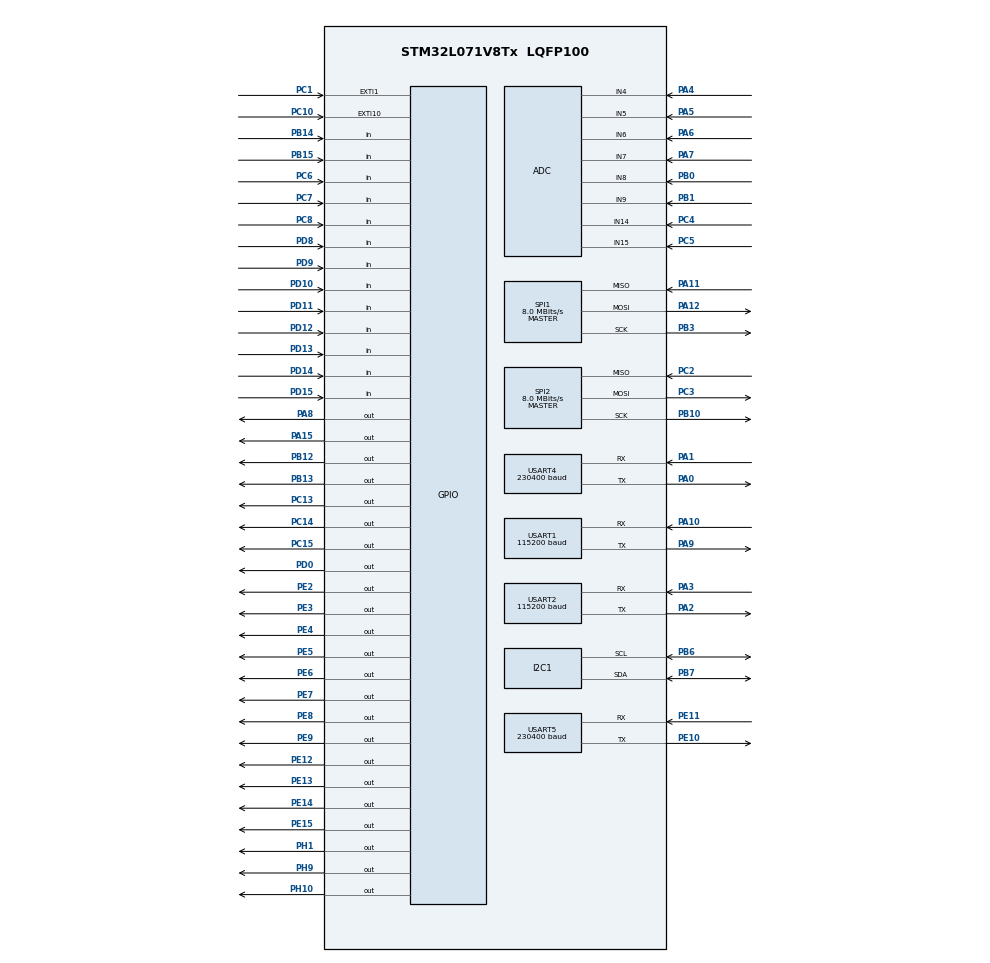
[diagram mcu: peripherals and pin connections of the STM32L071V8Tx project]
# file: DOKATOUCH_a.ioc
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CRC.InputDataFormat=CRC_INPUTDATA_FORMAT_HALFWORDS
I2C1.Timing=0x00303D5B
Mcu.Family=STM32L0
Mcu.Name=STM32L071V8Tx
Mcu.Package=LQFP100
NVIC.TIM2_IRQn=true\:0\:0\:false\:false\:true\:true\:true\:true
NVIC.USART1_IRQn=true\:0\:0\:false\:false\:true\:true\:true\:true
NVIC.USART2_IRQn=true\:0\:0\:false\:false\:true\:true\:true\:true
NVIC.USART4_5_IRQn=true\:0\:0\:false\:false\:true\:true\:true\:true
PA0.Mode=Asynchronous
PA0.Signal=USART4_TX
PA1.Mode=Asynchronous
PA1.Signal=USART4_RX
PA10.Mode=Asynchronous
PA10.Signal=USART1_RX
PA11.Mode=Full_Duplex_Master
PA11.Signal=SPI1_MISO
PA12.Mode=Full_Duplex_Master
PA12.Signal=SPI1_MOSI
PA13.Mode=Serial_Wire
PA13.Signal=SYS_SWDIO
PA14.Mode=Serial_Wire
PA14.Signal=SYS_SWCLK
PA15.Signal=GPIO_Output
PA2.Mode=Asynchronous
PA2.Signal=USART2_TX
PA3.Mode=Asynchronous
PA3.Signal=USART2_RX
PA4.Mode=IN4
PA4.Signal=ADC_IN4
PA5.Mode=IN5
PA5.Signal=ADC_IN5
PA6.Mode=IN6
PA6.Signal=ADC_IN6
PA7.Mode=IN7
PA7.Signal=ADC_IN7
PA8.Signal=GPIO_Output
PA9.Mode=Asynchronous
PA9.Signal=USART1_TX
PB0.Mode=IN8
PB0.Signal=ADC_IN8
PB1.Mode=IN9
PB1.Signal=ADC_IN9
PB10.Mode=Full_Duplex_Master
PB10.Signal=SPI2_SCK
PB12.Signal=GPIO_Output
PB13.Signal=GPIO_Output
PB14.Signal=GPIO_Input
PB15.Signal=GPIO_Input
PB3.Mode=Full_Duplex_Master
PB3.Signal=SPI1_SCK
PB6.Mode=I2C
PB6.Signal=I2C1_SCL
PB7.Mode=I2C
PB7.Signal=I2C1_SDA
PC1.Signal=GPXTI1
PC10.Signal=GPXTI10
PC13.Signal=GPIO_Output
PC14-OSC32_IN.Signal=GPIO_Output
PC15-OSC32_OUT.Signal=GPIO_Output
PC2.Mode=Full_Duplex_Master
PC2.Signal=SPI2_MISO
PC3.Mode=Full_Duplex_Master
PC3.Signal=SPI2_MOSI
PC4.Mode=IN14
PC4.Signal=ADC_IN14
PC5.Mode=IN15
PC5.Signal=ADC_IN15
PC6.Signal=GPIO_Input
PC7.Signal=GPIO_Input
PC8.Signal=GPIO_Input
PD0.Signal=GPIO_Output
PD10.Signal=GPIO_Input
PD11.Signal=GPIO_Input
PD12.Signal=GPIO_Input
PD13.Signal=GPIO_Input
PD14.Signal=GPIO_Input
PD15.Signal=GPIO_Input
PD8.Signal=GPIO_Input
PD9.Signal=GPIO_Input
PE10.Mode=Asynchronous
PE10.Signal=USART5_TX
PE11.Mode=Asynchronous
PE11.Signal=USART5_RX
PE12.Signal=GPIO_Output
PE13.Signal=GPIO_Output
PE14.Signal=GPIO_Output
PE15.Signal=GPIO_Output
PE2.Signal=GPIO_Output
PE3.Signal=GPIO_Output
PE4.Signal=GPIO_Output
PE5.Signal=GPIO_Output
PE6.Signal=GPIO_Output
PE7.Signal=GPIO_Output
PE8.Signal=GPIO_Output
PE9.Signal=GPIO_Output
PH1-OSC_OUT.Signal=GPIO_Output
PH10.Signal=GPIO_Output
PH9.Signal=GPIO_Output
ProjectManager.HeapSize=0x200
ProjectManager.StackSize=0x400
ProjectManager.TargetToolchain=MDK-ARM V5
RCC.AHBFreq_Value=16000000
RCC.APB1Freq_Value=16000000
RCC.APB1TimFreq_Value=16000000
RCC.APB2Freq_Value=16000000
RCC.APB2TimFreq_Value=16000000
RCC.HCLKFreq_Value=16000000
RCC.HSE_VALUE=8000000
RCC.HSI16_VALUE=16000000
RCC.HSI_VALUE=16000000
RCC.LSE_VALUE=32768
RCC.MSI_VALUE=2097000
RCC.PLLMUL=RCC_PLLMUL_4
RCC.SYSCLKFreq_VALUE=16000000
RCC.SYSCLKSource=RCC_SYSCLKSOURCE_HSI
RCC.VCOOutputFreq_Value=64000000
SPI1.CalculateBaudRate=8.0 MBits/s
SPI1.Direction=SPI_DIRECTION_2LINES
SPI1.Mode=SPI_MODE_MASTER
SPI1.VirtualType=VM_MASTER
SPI2.CalculateBaudRate=8.0 MBits/s
SPI2.Direction=SPI_DIRECTION_2LINES
SPI2.Mode=SPI_MODE_MASTER
SPI2.VirtualType=VM_MASTER
USART1.BaudRate=115200
USART1.Parity=PARITY_NONE
USART1.VirtualMode-Asynchronous=VM_ASYNC
USART1.WordLength=WORDLENGTH_8B
USART2.BaudRate=115200
USART2.VirtualMode-Asynchronous=VM_ASYNC
USART2.WordLength=WORDLENGTH_8B
USART4.BaudRate=230400
USART4.Parity=PARITY_NONE
USART4.VirtualMode-Asynchronous=VM_ASYNC
USART4.WordLength=WORDLENGTH_8B
USART5.BaudRate=230400
USART5.Parity=PARITY_NONE
USART5.VirtualMode-Asynchronous=VM_ASYNC
USART5.WordLength=WORDLENGTH_8B
VP_CRC_VS_CRC.Mode=CRC_Activate
VP_TIM2_VS_ClockSourceINT.Mode=Internal
board=DOKATOUCH_a

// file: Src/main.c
/**
  ******************************************************************************
  * File Name          : main.c
  * Description        : Main program body
  ******************************************************************************
  ** This notice applies to any and all portions of this file
  * that are not between comment pairs USER CODE BEGIN and
  * USER CODE END. Other portions of this file, whether
  * inserted by the user or by software development tools
  * are owned by their respective copyright owners.
  *
  * COPYRIGHT(c) 2024 STMicroelectronics
  *
  * Redistribution and use in source and binary forms, with or without modification,
  * are permitted provided that the following conditions are met:
  *   1. Redistributions of source code must retain the above copyright notice,
  *      this list of conditions and the following disclaimer.
  *   2. Redistributions in binary form must reproduce the above copyright notice,
  *      this list of conditions and the following disclaimer in the documentation
  *      and/or other materials provided with the distribution.
  *   3. Neither the name of STMicroelectronics nor the names of its contributors
  *      may be used to endorse or promote products derived from this software
  *      without specific prior written permission.
  *
  * THIS SOFTWARE IS PROVIDED BY THE COPYRIGHT HOLDERS AND CONTRIBUTORS "AS IS"
  * AND ANY EXPRESS OR IMPLIED WARRANTIES, INCLUDING, BUT NOT LIMITED TO, THE
  * IMPLIED WARRANTIES OF MERCHANTABILITY AND FITNESS FOR A PARTICULAR PURPOSE ARE
  * DISCLAIMED. IN NO EVENT SHALL THE COPYRIGHT HOLDER OR CONTRIBUTORS BE LIABLE
  * FOR ANY DIRECT, INDIRECT, INCIDENTAL, SPECIAL, EXEMPLARY, OR CONSEQUENTIAL
  * DAMAGES (INCLUDING, BUT NOT LIMITED TO, PROCUREMENT OF SUBSTITUTE GOODS OR
  * SERVICES; LOSS OF USE, DATA, OR PROFITS; OR BUSINESS INTERRUPTION) HOWEVER
  * CAUSED AND ON ANY THEORY OF LIABILITY, WHETHER IN CONTRACT, STRICT LIABILITY,
  * OR TORT (INCLUDING NEGLIGENCE OR OTHERWISE) ARISING IN ANY WAY OUT OF THE USE
  * OF THIS SOFTWARE, EVEN IF ADVISED OF THE POSSIBILITY OF SUCH DAMAGE.
  *
  ******************************************************************************
  */
#include "main.h"

/* USER CODE BEGIN Includes */

/*
2022.11.10 add tilt stop function.

*/

/* USER CODE END Includes */

/* USER CODE BEGIN PV */
/* Private variables ---------------------------------------------------------*/

/* USER CODE END PV */

static void LL_Init(void);
void SystemClock_Config(void);
static void MX_GPIO_Init(void);
static void MX_ADC_Init(void);
static void MX_CRC_Init(void);
static void MX_I2C1_Init(void);
static void MX_SPI1_Init(void);
static void MX_SPI2_Init(void);
static void MX_USART1_UART_Init(void);
static void MX_USART2_UART_Init(void);
static void MX_USART4_UART_Init(void);
static void MX_USART5_UART_Init(void);
static void MX_TIM2_Init(void);

/* USER CODE BEGIN PFP */
/* Private function prototypes -----------------------------------------------*/

/* USER CODE END PFP */

int main(void)
{

  /* MCU Configuration----------------------------------------------------------*/

  /* Reset of all peripherals, Initializes the Flash interface and the Systick. */
  LL_Init();

  /* Configure the system clock */
  SystemClock_Config();

  /* Initialize all configured peripherals */
  MX_GPIO_Init();
  MX_ADC_Init();
  MX_CRC_Init();
  MX_I2C1_Init();
  MX_SPI1_Init();
  MX_SPI2_Init();
  MX_USART1_UART_Init();
  MX_USART2_UART_Init();
  MX_USART4_UART_Init();
  MX_USART5_UART_Init();
  MX_TIM2_Init();

  /* USER CODE BEGIN 2 */
//	u5RxInterruptEnable();
	u4RxInterruptEnable();
	u2RxInterruptEnable();
	u1RxInterruptEnable();

	initTimers();
	initIwdg();

	initKanaPilotBH();

	pato1Off();
  blink(3);
	pato1On();

  /* USER CODE END 2 */

  /* Infinite loop */
  /* USER CODE BEGIN WHILE */
  while (1)
  {

		resetWDT();
		mainKanaPilotBH();

  /* USER CODE END WHILE */

  }

}

static void LL_Init(void)
{

  LL_APB2_GRP1_EnableClock(LL_APB2_GRP1_PERIPH_SYSCFG);
  LL_APB1_GRP1_EnableClock(LL_APB1_GRP1_PERIPH_PWR);

  /* System interrupt init*/
  /* SVC_IRQn interrupt configuration */
  NVIC_SetPriority(SVC_IRQn, 0);
  /* PendSV_IRQn interrupt configuration */
  NVIC_SetPriority(PendSV_IRQn, 0);
  /* SysTick_IRQn interrupt configuration */
  NVIC_SetPriority(SysTick_IRQn, 0);

}

/** System Clock Configuration
*/
void SystemClock_Config(void)
{

  LL_FLASH_SetLatency(LL_FLASH_LATENCY_0);

  if(LL_FLASH_GetLatency() != LL_FLASH_LATENCY_0)
  {
  Error_Handler();
  }
  LL_PWR_SetRegulVoltageScaling(LL_PWR_REGU_VOLTAGE_SCALE1);

  LL_RCC_HSI_Enable();

   /* Wait till HSI is ready */
  while(LL_RCC_HSI_IsReady() != 1)
  {

  }
  LL_RCC_HSI_SetCalibTrimming(16);

  LL_RCC_SetAHBPrescaler(LL_RCC_SYSCLK_DIV_1);

  LL_RCC_SetAPB1Prescaler(LL_RCC_APB1_DIV_1);

  LL_RCC_SetAPB2Prescaler(LL_RCC_APB2_DIV_1);

  LL_RCC_SetSysClkSource(LL_RCC_SYS_CLKSOURCE_HSI);

   /* Wait till System clock is ready */
  while(LL_RCC_GetSysClkSource() != LL_RCC_SYS_CLKSOURCE_STATUS_HSI)
  {

  }
  LL_Init1msTick(16000000);

  LL_SYSTICK_SetClkSource(LL_SYSTICK_CLKSOURCE_HCLK);

  LL_SetSystemCoreClock(16000000);

  LL_RCC_SetUSARTClockSource(LL_RCC_USART1_CLKSOURCE_PCLK2);

  LL_RCC_SetUSARTClockSource(LL_RCC_USART2_CLKSOURCE_PCLK1);

  LL_RCC_SetI2CClockSource(LL_RCC_I2C1_CLKSOURCE_PCLK1);

  /* SysTick_IRQn interrupt configuration */
  NVIC_SetPriority(SysTick_IRQn, 0);
}

/* ADC init function */
static void MX_ADC_Init(void)
{

  LL_ADC_InitTypeDef ADC_InitStruct;
  LL_ADC_REG_InitTypeDef ADC_REG_InitStruct;

  LL_GPIO_InitTypeDef GPIO_InitStruct;

  /* Peripheral clock enable */
  LL_APB2_GRP1_EnableClock(LL_APB2_GRP1_PERIPH_ADC1);

  /**ADC GPIO Configuration
  PA4   ------> ADC_IN4
  PA5   ------> ADC_IN5
  PA6   ------> ADC_IN6
  PA7   ------> ADC_IN7
  PC4   ------> ADC_IN14
  PC5   ------> ADC_IN15
  PB0   ------> ADC_IN8
  PB1   ------> ADC_IN9
  */
  GPIO_InitStruct.Pin = LL_GPIO_PIN_4;
  GPIO_InitStruct.Mode = LL_GPIO_MODE_ANALOG;
  GPIO_InitStruct.Pull = LL_GPIO_PULL_NO;
  LL_GPIO_Init(GPIOA, &GPIO_InitStruct);

  GPIO_InitStruct.Pin = LL_GPIO_PIN_5;
  GPIO_InitStruct.Mode = LL_GPIO_MODE_ANALOG;
  GPIO_InitStruct.Pull = LL_GPIO_PULL_NO;
  LL_GPIO_Init(GPIOA, &GPIO_InitStruct);

  GPIO_InitStruct.Pin = LL_GPIO_PIN_6;
  GPIO_InitStruct.Mode = LL_GPIO_MODE_ANALOG;
  GPIO_InitStruct.Pull = LL_GPIO_PULL_NO;
  LL_GPIO_Init(GPIOA, &GPIO_InitStruct);

  GPIO_InitStruct.Pin = LL_GPIO_PIN_7;
  GPIO_InitStruct.Mode = LL_GPIO_MODE_ANALOG;
  GPIO_InitStruct.Pull = LL_GPIO_PULL_NO;
  LL_GPIO_Init(GPIOA, &GPIO_InitStruct);

  GPIO_InitStruct.Pin = LL_GPIO_PIN_4;
  GPIO_InitStruct.Mode = LL_GPIO_MODE_ANALOG;
  GPIO_InitStruct.Pull = LL_GPIO_PULL_NO;
  LL_GPIO_Init(GPIOC, &GPIO_InitStruct);

  GPIO_InitStruct.Pin = LL_GPIO_PIN_5;
  GPIO_InitStruct.Mode = LL_GPIO_MODE_ANALOG;
  GPIO_InitStruct.Pull = LL_GPIO_PULL_NO;
  LL_GPIO_Init(GPIOC, &GPIO_InitStruct);

  GPIO_InitStruct.Pin = LL_GPIO_PIN_0;
  GPIO_InitStruct.Mode = LL_GPIO_MODE_ANALOG;
  GPIO_InitStruct.Pull = LL_GPIO_PULL_NO;
  LL_GPIO_Init(GPIOB, &GPIO_InitStruct);

  GPIO_InitStruct.Pin = LL_GPIO_PIN_1;
  GPIO_InitStruct.Mode = LL_GPIO_MODE_ANALOG;
  GPIO_InitStruct.Pull = LL_GPIO_PULL_NO;
  LL_GPIO_Init(GPIOB, &GPIO_InitStruct);

    /**Configure Regular Channel
    */
  LL_ADC_REG_SetSequencerChannels(ADC1, LL_ADC_CHANNEL_4);

    /**Configure Regular Channel
    */
  LL_ADC_REG_SetSequencerChannels(ADC1, LL_ADC_CHANNEL_5);

    /**Configure Regular Channel
    */
  LL_ADC_REG_SetSequencerChannels(ADC1, LL_ADC_CHANNEL_6);

    /**Configure Regular Channel
    */
  LL_ADC_REG_SetSequencerChannels(ADC1, LL_ADC_CHANNEL_7);

    /**Configure Regular Channel
    */
  LL_ADC_REG_SetSequencerChannels(ADC1, LL_ADC_CHANNEL_8);

    /**Configure Regular Channel
    */
  LL_ADC_REG_SetSequencerChannels(ADC1, LL_ADC_CHANNEL_9);

    /**Configure Regular Channel
    */
  LL_ADC_REG_SetSequencerChannels(ADC1, LL_ADC_CHANNEL_14);

    /**Configure Regular Channel
    */
  LL_ADC_REG_SetSequencerChannels(ADC1, LL_ADC_CHANNEL_15);

    /**Common config
    */
  ADC_InitStruct.Resolution = LL_ADC_RESOLUTION_12B;
  ADC_InitStruct.DataAlignment = LL_ADC_DATA_ALIGN_RIGHT;
  ADC_InitStruct.LowPowerMode = LL_ADC_LP_MODE_NONE;
  LL_ADC_Init(ADC1, &ADC_InitStruct);

  ADC_REG_InitStruct.TriggerSource = LL_ADC_REG_TRIG_SOFTWARE;
  ADC_REG_InitStruct.SequencerDiscont = LL_ADC_REG_SEQ_DISCONT_DISABLE;
  ADC_REG_InitStruct.ContinuousMode = LL_ADC_REG_CONV_SINGLE;
  ADC_REG_InitStruct.DMATransfer = LL_ADC_REG_DMA_TRANSFER_LIMITED;
  ADC_REG_InitStruct.Overrun = LL_ADC_REG_OVR_DATA_PRESERVED;
  LL_ADC_REG_Init(ADC1, &ADC_REG_InitStruct);

  LL_ADC_SetClock(ADC1, LL_ADC_CLOCK_SYNC_PCLK_DIV1);

  LL_ADC_SetSamplingTimeCommonChannels(ADC1, LL_ADC_SAMPLINGTIME_1CYCLE_5);

  LL_ADC_SetOverSamplingScope(ADC1, LL_ADC_OVS_DISABLE);

  LL_ADC_SetCommonFrequencyMode(__LL_ADC_COMMON_INSTANCE(ADC1), LL_ADC_CLOCK_FREQ_MODE_HIGH);

  LL_ADC_EnableIT_EOC(ADC1);

  LL_ADC_DisableIT_EOS(ADC1);

}

/* CRC init function */
static void MX_CRC_Init(void)
{

  /* Peripheral clock enable */
  LL_AHB1_GRP1_EnableClock(LL_AHB1_GRP1_PERIPH_CRC);

  LL_CRC_SetInputDataReverseMode(CRC, LL_CRC_INDATA_REVERSE_NONE);

  LL_CRC_SetOutputDataReverseMode(CRC, LL_CRC_OUTDATA_REVERSE_NONE);

  LL_CRC_SetPolynomialCoef(CRC, LL_CRC_DEFAULT_CRC32_POLY);

  LL_CRC_SetPolynomialSize(CRC, LL_CRC_POLYLENGTH_32B);

  LL_CRC_SetInitialData(CRC, LL_CRC_DEFAULT_CRC_INITVALUE);

}

/* I2C1 init function */
static void MX_I2C1_Init(void)
{

  LL_I2C_InitTypeDef I2C_InitStruct;

  LL_GPIO_InitTypeDef GPIO_InitStruct;

  /**I2C1 GPIO Configuration
  PB6   ------> I2C1_SCL
  PB7   ------> I2C1_SDA
  */
  GPIO_InitStruct.Pin = LL_GPIO_PIN_6;
  GPIO_InitStruct.Mode = LL_GPIO_MODE_ALTERNATE;
  GPIO_InitStruct.Speed = LL_GPIO_SPEED_FREQ_VERY_HIGH;
  GPIO_InitStruct.OutputType = LL_GPIO_OUTPUT_OPENDRAIN;
  GPIO_InitStruct.Pull = LL_GPIO_PULL_UP;
  GPIO_InitStruct.Alternate = LL_GPIO_AF_1;
  LL_GPIO_Init(GPIOB, &GPIO_InitStruct);

  GPIO_InitStruct.Pin = LL_GPIO_PIN_7;
  GPIO_InitStruct.Mode = LL_GPIO_MODE_ALTERNATE;
  GPIO_InitStruct.Speed = LL_GPIO_SPEED_FREQ_VERY_HIGH;
  GPIO_InitStruct.OutputType = LL_GPIO_OUTPUT_OPENDRAIN;
  GPIO_InitStruct.Pull = LL_GPIO_PULL_UP;
  GPIO_InitStruct.Alternate = LL_GPIO_AF_1;
  LL_GPIO_Init(GPIOB, &GPIO_InitStruct);

  /* Peripheral clock enable */
  LL_APB1_GRP1_EnableClock(LL_APB1_GRP1_PERIPH_I2C1);

    /**I2C Initialization
    */
  I2C_InitStruct.PeripheralMode = LL_I2C_MODE_I2C;
  I2C_InitStruct.Timing = 0x00303D5B;
  I2C_InitStruct.AnalogFilter = LL_I2C_ANALOGFILTER_ENABLE;
  I2C_InitStruct.DigitalFilter = 0;
  I2C_InitStruct.OwnAddress1 = 0;
  I2C_InitStruct.TypeAcknowledge = LL_I2C_ACK;
  I2C_InitStruct.OwnAddrSize = LL_I2C_OWNADDRESS1_7BIT;
  LL_I2C_Init(I2C1, &I2C_InitStruct);

  LL_I2C_EnableAutoEndMode(I2C1);

  LL_I2C_SetOwnAddress2(I2C1, 0, LL_I2C_OWNADDRESS2_NOMASK);

  LL_I2C_DisableOwnAddress2(I2C1);

  LL_I2C_DisableGeneralCall(I2C1);

  LL_I2C_EnableClockStretching(I2C1);

}

/* SPI1 init function */
static void MX_SPI1_Init(void)
{

  LL_SPI_InitTypeDef SPI_InitStruct;

  LL_GPIO_InitTypeDef GPIO_InitStruct;

  /* Peripheral clock enable */
  LL_APB2_GRP1_EnableClock(LL_APB2_GRP1_PERIPH_SPI1);

  /**SPI1 GPIO Configuration
  PA11   ------> SPI1_MISO
  PA12   ------> SPI1_MOSI
  PB3   ------> SPI1_SCK
  */
  GPIO_InitStruct.Pin = LL_GPIO_PIN_11;
  GPIO_InitStruct.Mode = LL_GPIO_MODE_ALTERNATE;
  GPIO_InitStruct.Speed = LL_GPIO_SPEED_FREQ_VERY_HIGH;
  GPIO_InitStruct.OutputType = LL_GPIO_OUTPUT_PUSHPULL;
  GPIO_InitStruct.Pull = LL_GPIO_PULL_NO;
  GPIO_InitStruct.Alternate = LL_GPIO_AF_0;
  LL_GPIO_Init(GPIOA, &GPIO_InitStruct);

  GPIO_InitStruct.Pin = LL_GPIO_PIN_12;
  GPIO_InitStruct.Mode = LL_GPIO_MODE_ALTERNATE;
  GPIO_InitStruct.Speed = LL_GPIO_SPEED_FREQ_VERY_HIGH;
  GPIO_InitStruct.OutputType = LL_GPIO_OUTPUT_PUSHPULL;
  GPIO_InitStruct.Pull = LL_GPIO_PULL_NO;
  GPIO_InitStruct.Alternate = LL_GPIO_AF_0;
  LL_GPIO_Init(GPIOA, &GPIO_InitStruct);

  GPIO_InitStruct.Pin = LL_GPIO_PIN_3;
  GPIO_InitStruct.Mode = LL_GPIO_MODE_ALTERNATE;
  GPIO_InitStruct.Speed = LL_GPIO_SPEED_FREQ_VERY_HIGH;
  GPIO_InitStruct.OutputType = LL_GPIO_OUTPUT_PUSHPULL;
  GPIO_InitStruct.Pull = LL_GPIO_PULL_NO;
  GPIO_InitStruct.Alternate = LL_GPIO_AF_0;
  LL_GPIO_Init(GPIOB, &GPIO_InitStruct);

  SPI_InitStruct.TransferDirection = LL_SPI_FULL_DUPLEX;
  SPI_InitStruct.Mode = LL_SPI_MODE_MASTER;
  SPI_InitStruct.DataWidth = LL_SPI_DATAWIDTH_8BIT;
  SPI_InitStruct.ClockPolarity = LL_SPI_POLARITY_LOW;
  SPI_InitStruct.ClockPhase = LL_SPI_PHASE_1EDGE;
  SPI_InitStruct.NSS = LL_SPI_NSS_SOFT;
  SPI_InitStruct.BaudRate = LL_SPI_BAUDRATEPRESCALER_DIV2;
  SPI_InitStruct.BitOrder = LL_SPI_MSB_FIRST;
  SPI_InitStruct.CRCCalculation = LL_SPI_CRCCALCULATION_DISABLE;
  SPI_InitStruct.CRCPoly = 7;
  LL_SPI_Init(SPI1, &SPI_InitStruct);

  LL_SPI_SetStandard(SPI1, LL_SPI_PROTOCOL_MOTOROLA);

}

/* SPI2 init function */
static void MX_SPI2_Init(void)
{

  LL_SPI_InitTypeDef SPI_InitStruct;

  LL_GPIO_InitTypeDef GPIO_InitStruct;

  /* Peripheral clock enable */
  LL_APB1_GRP1_EnableClock(LL_APB1_GRP1_PERIPH_SPI2);

  /**SPI2 GPIO Configuration
  PC2   ------> SPI2_MISO
  PC3   ------> SPI2_MOSI
  PB10   ------> SPI2_SCK
  */
  GPIO_InitStruct.Pin = LL_GPIO_PIN_2;
  GPIO_InitStruct.Mode = LL_GPIO_MODE_ALTERNATE;
  GPIO_InitStruct.Speed = LL_GPIO_SPEED_FREQ_VERY_HIGH;
  GPIO_InitStruct.OutputType = LL_GPIO_OUTPUT_PUSHPULL;
  GPIO_InitStruct.Pull = LL_GPIO_PULL_NO;
  GPIO_InitStruct.Alternate = LL_GPIO_AF_2;
  LL_GPIO_Init(GPIOC, &GPIO_InitStruct);

  GPIO_InitStruct.Pin = LL_GPIO_PIN_3;
  GPIO_InitStruct.Mode = LL_GPIO_MODE_ALTERNATE;
  GPIO_InitStruct.Speed = LL_GPIO_SPEED_FREQ_VERY_HIGH;
  GPIO_InitStruct.OutputType = LL_GPIO_OUTPUT_PUSHPULL;
  GPIO_InitStruct.Pull = LL_GPIO_PULL_NO;
  GPIO_InitStruct.Alternate = LL_GPIO_AF_2;
  LL_GPIO_Init(GPIOC, &GPIO_InitStruct);

  GPIO_InitStruct.Pin = LL_GPIO_PIN_10;
  GPIO_InitStruct.Mode = LL_GPIO_MODE_ALTERNATE;
  GPIO_InitStruct.Speed = LL_GPIO_SPEED_FREQ_VERY_HIGH;
  GPIO_InitStruct.OutputType = LL_GPIO_OUTPUT_PUSHPULL;
  GPIO_InitStruct.Pull = LL_GPIO_PULL_NO;
  GPIO_InitStruct.Alternate = LL_GPIO_AF_5;
  LL_GPIO_Init(GPIOB, &GPIO_InitStruct);

  SPI_InitStruct.TransferDirection = LL_SPI_FULL_DUPLEX;
  SPI_InitStruct.Mode = LL_SPI_MODE_MASTER;
  SPI_InitStruct.DataWidth = LL_SPI_DATAWIDTH_8BIT;
  SPI_InitStruct.ClockPolarity = LL_SPI_POLARITY_LOW;
  SPI_InitStruct.ClockPhase = LL_SPI_PHASE_1EDGE;
  SPI_InitStruct.NSS = LL_SPI_NSS_SOFT;
  SPI_InitStruct.BaudRate = LL_SPI_BAUDRATEPRESCALER_DIV2;
  SPI_InitStruct.BitOrder = LL_SPI_MSB_FIRST;
  SPI_InitStruct.CRCCalculation = LL_SPI_CRCCALCULATION_DISABLE;
  SPI_InitStruct.CRCPoly = 7;
  LL_SPI_Init(SPI2, &SPI_InitStruct);

  LL_SPI_SetStandard(SPI2, LL_SPI_PROTOCOL_MOTOROLA);

}

/* TIM2 init function */
static void MX_TIM2_Init(void)
{

  LL_TIM_InitTypeDef TIM_InitStruct;

  /* Peripheral clock enable */
  LL_APB1_GRP1_EnableClock(LL_APB1_GRP1_PERIPH_TIM2);

  /* TIM2 interrupt Init */
  NVIC_SetPriority(TIM2_IRQn, 0);
  NVIC_EnableIRQ(TIM2_IRQn);

  TIM_InitStruct.Prescaler = 0;
  TIM_InitStruct.CounterMode = LL_TIM_COUNTERMODE_UP;
  TIM_InitStruct.Autoreload = 0;
  TIM_InitStruct.ClockDivision = LL_TIM_CLOCKDIVISION_DIV1;
  LL_TIM_Init(TIM2, &TIM_InitStruct);

  LL_TIM_SetClockSource(TIM2, LL_TIM_CLOCKSOURCE_INTERNAL);

  LL_TIM_SetTriggerOutput(TIM2, LL_TIM_TRGO_RESET);

  LL_TIM_DisableMasterSlaveMode(TIM2);

}

/* USART1 init function */
static void MX_USART1_UART_Init(void)
{

  LL_USART_InitTypeDef USART_InitStruct;

  LL_GPIO_InitTypeDef GPIO_InitStruct;

  /* Peripheral clock enable */
  LL_APB2_GRP1_EnableClock(LL_APB2_GRP1_PERIPH_USART1);

  /**USART1 GPIO Configuration
  PA9   ------> USART1_TX
  PA10   ------> USART1_RX
  */
  GPIO_InitStruct.Pin = LL_GPIO_PIN_9;
  GPIO_InitStruct.Mode = LL_GPIO_MODE_ALTERNATE;
  GPIO_InitStruct.Speed = LL_GPIO_SPEED_FREQ_VERY_HIGH;
  GPIO_InitStruct.OutputType = LL_GPIO_OUTPUT_PUSHPULL;
  GPIO_InitStruct.Pull = LL_GPIO_PULL_UP;
  GPIO_InitStruct.Alternate = LL_GPIO_AF_4;
  LL_GPIO_Init(GPIOA, &GPIO_InitStruct);

  GPIO_InitStruct.Pin = LL_GPIO_PIN_10;
  GPIO_InitStruct.Mode = LL_GPIO_MODE_ALTERNATE;
  GPIO_InitStruct.Speed = LL_GPIO_SPEED_FREQ_VERY_HIGH;
  GPIO_InitStruct.OutputType = LL_GPIO_OUTPUT_PUSHPULL;
  GPIO_InitStruct.Pull = LL_GPIO_PULL_UP;
  GPIO_InitStruct.Alternate = LL_GPIO_AF_4;
  LL_GPIO_Init(GPIOA, &GPIO_InitStruct);

  /* USART1 interrupt Init */
  NVIC_SetPriority(USART1_IRQn, 0);
  NVIC_EnableIRQ(USART1_IRQn);

  USART_InitStruct.BaudRate = 115200;
  USART_InitStruct.DataWidth = LL_USART_DATAWIDTH_8B;
  USART_InitStruct.StopBits = LL_USART_STOPBITS_1;
  USART_InitStruct.Parity = LL_USART_PARITY_NONE;
  USART_InitStruct.TransferDirection = LL_USART_DIRECTION_TX_RX;
  USART_InitStruct.HardwareFlowControl = LL_USART_HWCONTROL_NONE;
  USART_InitStruct.OverSampling = LL_USART_OVERSAMPLING_16;
  LL_USART_Init(USART1, &USART_InitStruct);

  LL_USART_DisableOverrunDetect(USART1);

  LL_USART_ConfigAsyncMode(USART1);

  LL_USART_Enable(USART1);

}

/* USART2 init function */
static void MX_USART2_UART_Init(void)
{

  LL_USART_InitTypeDef USART_InitStruct;

  LL_GPIO_InitTypeDef GPIO_InitStruct;

  /* Peripheral clock enable */
  LL_APB1_GRP1_EnableClock(LL_APB1_GRP1_PERIPH_USART2);

  /**USART2 GPIO Configuration
  PA2   ------> USART2_TX
  PA3   ------> USART2_RX
  */
  GPIO_InitStruct.Pin = LL_GPIO_PIN_2;
  GPIO_InitStruct.Mode = LL_GPIO_MODE_ALTERNATE;
  GPIO_InitStruct.Speed = LL_GPIO_SPEED_FREQ_VERY_HIGH;
  GPIO_InitStruct.OutputType = LL_GPIO_OUTPUT_PUSHPULL;
  GPIO_InitStruct.Pull = LL_GPIO_PULL_UP;
  GPIO_InitStruct.Alternate = LL_GPIO_AF_4;
  LL_GPIO_Init(GPIOA, &GPIO_InitStruct);

  GPIO_InitStruct.Pin = LL_GPIO_PIN_3;
  GPIO_InitStruct.Mode = LL_GPIO_MODE_ALTERNATE;
  GPIO_InitStruct.Speed = LL_GPIO_SPEED_FREQ_VERY_HIGH;
  GPIO_InitStruct.OutputType = LL_GPIO_OUTPUT_PUSHPULL;
  GPIO_InitStruct.Pull = LL_GPIO_PULL_UP;
  GPIO_InitStruct.Alternate = LL_GPIO_AF_4;
  LL_GPIO_Init(GPIOA, &GPIO_InitStruct);

  /* USART2 interrupt Init */
  NVIC_SetPriority(USART2_IRQn, 0);
  NVIC_EnableIRQ(USART2_IRQn);

  USART_InitStruct.BaudRate = 115200;
  USART_InitStruct.DataWidth = LL_USART_DATAWIDTH_8B;
  USART_InitStruct.StopBits = LL_USART_STOPBITS_1;
  USART_InitStruct.Parity = LL_USART_PARITY_NONE;
  USART_InitStruct.TransferDirection = LL_USART_DIRECTION_TX_RX;
  USART_InitStruct.HardwareFlowControl = LL_USART_HWCONTROL_NONE;
  USART_InitStruct.OverSampling = LL_USART_OVERSAMPLING_16;
  LL_USART_Init(USART2, &USART_InitStruct);

  LL_USART_DisableOverrunDetect(USART2);

  LL_USART_ConfigAsyncMode(USART2);

  LL_USART_Enable(USART2);

}

/* USART4 init function */
static void MX_USART4_UART_Init(void)
{

  LL_USART_InitTypeDef USART_InitStruct;

  LL_GPIO_InitTypeDef GPIO_InitStruct;

  /* Peripheral clock enable */
  LL_APB1_GRP1_EnableClock(LL_APB1_GRP1_PERIPH_USART4);

  /**USART4 GPIO Configuration
  PA0   ------> USART4_TX
  PA1   ------> USART4_RX
  */
  GPIO_InitStruct.Pin = LL_GPIO_PIN_0;
  GPIO_InitStruct.Mode = LL_GPIO_MODE_ALTERNATE;
  GPIO_InitStruct.Speed = LL_GPIO_SPEED_FREQ_VERY_HIGH;
  GPIO_InitStruct.OutputType = LL_GPIO_OUTPUT_PUSHPULL;
  GPIO_InitStruct.Pull = LL_GPIO_PULL_UP;
  GPIO_InitStruct.Alternate = LL_GPIO_AF_6;
  LL_GPIO_Init(GPIOA, &GPIO_InitStruct);

  GPIO_InitStruct.Pin = LL_GPIO_PIN_1;
  GPIO_InitStruct.Mode = LL_GPIO_MODE_ALTERNATE;
  GPIO_InitStruct.Speed = LL_GPIO_SPEED_FREQ_VERY_HIGH;
  GPIO_InitStruct.OutputType = LL_GPIO_OUTPUT_PUSHPULL;
  GPIO_InitStruct.Pull = LL_GPIO_PULL_UP;
  GPIO_InitStruct.Alternate = LL_GPIO_AF_6;
  LL_GPIO_Init(GPIOA, &GPIO_InitStruct);

  /* USART4 interrupt Init */
  NVIC_SetPriority(USART4_5_IRQn, 0);
  NVIC_EnableIRQ(USART4_5_IRQn);

  USART_InitStruct.BaudRate = 230400;
  USART_InitStruct.DataWidth = LL_USART_DATAWIDTH_8B;
  USART_InitStruct.StopBits = LL_USART_STOPBITS_1;
  USART_InitStruct.Parity = LL_USART_PARITY_NONE;
  USART_InitStruct.TransferDirection = LL_USART_DIRECTION_TX_RX;
  USART_InitStruct.HardwareFlowControl = LL_USART_HWCONTROL_NONE;
  USART_InitStruct.OverSampling = LL_USART_OVERSAMPLING_16;
  LL_USART_Init(USART4, &USART_InitStruct);

  LL_USART_DisableOverrunDetect(USART4);

  LL_USART_ConfigAsyncMode(USART4);

  LL_USART_Enable(USART4);

}

/* USART5 init function */
static void MX_USART5_UART_Init(void)
{

  LL_USART_InitTypeDef USART_InitStruct;

  LL_GPIO_InitTypeDef GPIO_InitStruct;

  /* Peripheral clock enable */
  LL_APB1_GRP1_EnableClock(LL_APB1_GRP1_PERIPH_USART5);

  /**USART5 GPIO Configuration
  PE10   ------> USART5_TX
  PE11   ------> USART5_RX
  */
  GPIO_InitStruct.Pin = LL_GPIO_PIN_10;
  GPIO_InitStruct.Mode = LL_GPIO_MODE_ALTERNATE;
  GPIO_InitStruct.Speed = LL_GPIO_SPEED_FREQ_VERY_HIGH;
  GPIO_InitStruct.OutputType = LL_GPIO_OUTPUT_PUSHPULL;
  GPIO_InitStruct.Pull = LL_GPIO_PULL_UP;
  GPIO_InitStruct.Alternate = LL_GPIO_AF_6;
  LL_GPIO_Init(GPIOE, &GPIO_InitStruct);

  GPIO_InitStruct.Pin = LL_GPIO_PIN_11;
  GPIO_InitStruct.Mode = LL_GPIO_MODE_ALTERNATE;
  GPIO_InitStruct.Speed = LL_GPIO_SPEED_FREQ_VERY_HIGH;
  GPIO_InitStruct.OutputType = LL_GPIO_OUTPUT_PUSHPULL;
  GPIO_InitStruct.Pull = LL_GPIO_PULL_UP;
  GPIO_InitStruct.Alternate = LL_GPIO_AF_6;
  LL_GPIO_Init(GPIOE, &GPIO_InitStruct);

  /* USART5 interrupt Init */
  NVIC_SetPriority(USART4_5_IRQn, 0);
  NVIC_EnableIRQ(USART4_5_IRQn);

  USART_InitStruct.BaudRate = 230400;
  USART_InitStruct.DataWidth = LL_USART_DATAWIDTH_8B;
  USART_InitStruct.StopBits = LL_USART_STOPBITS_1;
  USART_InitStruct.Parity = LL_USART_PARITY_NONE;
  USART_InitStruct.TransferDirection = LL_USART_DIRECTION_TX_RX;
  USART_InitStruct.HardwareFlowControl = LL_USART_HWCONTROL_NONE;
  USART_InitStruct.OverSampling = LL_USART_OVERSAMPLING_16;
  LL_USART_Init(USART5, &USART_InitStruct);

  LL_USART_DisableOverrunDetect(USART5);

  LL_USART_ConfigAsyncMode(USART5);

  LL_USART_Enable(USART5);

}

/** Configure pins as
        * Analog
        * Input
        * Output
        * EVENT_OUT
        * EXTI
*/
static void MX_GPIO_Init(void)
{

  LL_EXTI_InitTypeDef EXTI_InitStruct;
  LL_GPIO_InitTypeDef GPIO_InitStruct;

  /* GPIO Ports Clock Enable */
  LL_IOP_GRP1_EnableClock(LL_IOP_GRP1_PERIPH_GPIOE);
  LL_IOP_GRP1_EnableClock(LL_IOP_GRP1_PERIPH_GPIOC);
  LL_IOP_GRP1_EnableClock(LL_IOP_GRP1_PERIPH_GPIOH);
  LL_IOP_GRP1_EnableClock(LL_IOP_GRP1_PERIPH_GPIOA);
  LL_IOP_GRP1_EnableClock(LL_IOP_GRP1_PERIPH_GPIOB);
  LL_IOP_GRP1_EnableClock(LL_IOP_GRP1_PERIPH_GPIOD);

  /**/
  LL_GPIO_ResetOutputPin(GPIOE, LL_GPIO_PIN_2);

  /**/
  LL_GPIO_ResetOutputPin(GPIOE, LL_GPIO_PIN_3);

  /**/
  LL_GPIO_ResetOutputPin(GPIOE, LL_GPIO_PIN_4);

  /**/
  LL_GPIO_ResetOutputPin(GPIOE, LL_GPIO_PIN_5);

  /**/
  LL_GPIO_ResetOutputPin(GPIOE, LL_GPIO_PIN_6);

  /**/
  LL_GPIO_ResetOutputPin(GPIOC, LL_GPIO_PIN_13);

  /**/
  LL_GPIO_ResetOutputPin(GPIOC, LL_GPIO_PIN_14);

  /**/
  LL_GPIO_ResetOutputPin(GPIOC, LL_GPIO_PIN_15);

  /**/
  LL_GPIO_ResetOutputPin(GPIOH, LL_GPIO_PIN_9);

  /**/
  LL_GPIO_ResetOutputPin(GPIOH, LL_GPIO_PIN_10);

  /**/
  LL_GPIO_ResetOutputPin(GPIOH, LL_GPIO_PIN_1);

  /**/
  LL_GPIO_ResetOutputPin(GPIOE, LL_GPIO_PIN_7);

  /**/
  LL_GPIO_ResetOutputPin(GPIOE, LL_GPIO_PIN_8);

  /**/
  LL_GPIO_ResetOutputPin(GPIOE, LL_GPIO_PIN_9);

  /**/
  LL_GPIO_ResetOutputPin(GPIOE, LL_GPIO_PIN_12);

  /**/
  LL_GPIO_ResetOutputPin(GPIOE, LL_GPIO_PIN_13);

  /**/
  LL_GPIO_ResetOutputPin(GPIOE, LL_GPIO_PIN_14);

  /**/
  LL_GPIO_ResetOutputPin(GPIOE, LL_GPIO_PIN_15);

  /**/
  LL_GPIO_ResetOutputPin(GPIOB, LL_GPIO_PIN_12);

  /**/
  LL_GPIO_ResetOutputPin(GPIOB, LL_GPIO_PIN_13);

  /**/
  LL_GPIO_ResetOutputPin(GPIOA, LL_GPIO_PIN_8);

  /**/
  LL_GPIO_ResetOutputPin(GPIOA, LL_GPIO_PIN_15);

  /**/
  LL_GPIO_ResetOutputPin(GPIOD, LL_GPIO_PIN_0);

  /**/
  GPIO_InitStruct.Pin = LL_GPIO_PIN_2;
  GPIO_InitStruct.Mode = LL_GPIO_MODE_OUTPUT;
  GPIO_InitStruct.Speed = LL_GPIO_SPEED_FREQ_LOW;
  GPIO_InitStruct.OutputType = LL_GPIO_OUTPUT_PUSHPULL;
  GPIO_InitStruct.Pull = LL_GPIO_PULL_NO;
  LL_GPIO_Init(GPIOE, &GPIO_InitStruct);

  /**/
  GPIO_InitStruct.Pin = LL_GPIO_PIN_3;
  GPIO_InitStruct.Mode = LL_GPIO_MODE_OUTPUT;
  GPIO_InitStruct.Speed = LL_GPIO_SPEED_FREQ_LOW;
  GPIO_InitStruct.OutputType = LL_GPIO_OUTPUT_PUSHPULL;
  GPIO_InitStruct.Pull = LL_GPIO_PULL_NO;
  LL_GPIO_Init(GPIOE, &GPIO_InitStruct);

  /**/
  GPIO_InitStruct.Pin = LL_GPIO_PIN_4;
  GPIO_InitStruct.Mode = LL_GPIO_MODE_OUTPUT;
  GPIO_InitStruct.Speed = LL_GPIO_SPEED_FREQ_LOW;
  GPIO_InitStruct.OutputType = LL_GPIO_OUTPUT_PUSHPULL;
  GPIO_InitStruct.Pull = LL_GPIO_PULL_NO;
  LL_GPIO_Init(GPIOE, &GPIO_InitStruct);

  /**/
  GPIO_InitStruct.Pin = LL_GPIO_PIN_5;
  GPIO_InitStruct.Mode = LL_GPIO_MODE_OUTPUT;
  GPIO_InitStruct.Speed = LL_GPIO_SPEED_FREQ_LOW;
  GPIO_InitStruct.OutputType = LL_GPIO_OUTPUT_PUSHPULL;
  GPIO_InitStruct.Pull = LL_GPIO_PULL_NO;
  LL_GPIO_Init(GPIOE, &GPIO_InitStruct);

  /**/
  GPIO_InitStruct.Pin = LL_GPIO_PIN_6;
  GPIO_InitStruct.Mode = LL_GPIO_MODE_OUTPUT;
  GPIO_InitStruct.Speed = LL_GPIO_SPEED_FREQ_LOW;
  GPIO_InitStruct.OutputType = LL_GPIO_OUTPUT_PUSHPULL;
  GPIO_InitStruct.Pull = LL_GPIO_PULL_NO;
  LL_GPIO_Init(GPIOE, &GPIO_InitStruct);

  /**/
  GPIO_InitStruct.Pin = LL_GPIO_PIN_13;
  GPIO_InitStruct.Mode = LL_GPIO_MODE_OUTPUT;
  GPIO_InitStruct.Speed = LL_GPIO_SPEED_FREQ_LOW;
  GPIO_InitStruct.OutputType = LL_GPIO_OUTPUT_PUSHPULL;
  GPIO_InitStruct.Pull = LL_GPIO_PULL_NO;
  LL_GPIO_Init(GPIOC, &GPIO_InitStruct);

  /**/
  GPIO_InitStruct.Pin = LL_GPIO_PIN_14;
  GPIO_InitStruct.Mode = LL_GPIO_MODE_OUTPUT;
  GPIO_InitStruct.Speed = LL_GPIO_SPEED_FREQ_LOW;
  GPIO_InitStruct.OutputType = LL_GPIO_OUTPUT_PUSHPULL;
  GPIO_InitStruct.Pull = LL_GPIO_PULL_NO;
  LL_GPIO_Init(GPIOC, &GPIO_InitStruct);

  /**/
  GPIO_InitStruct.Pin = LL_GPIO_PIN_15;
  GPIO_InitStruct.Mode = LL_GPIO_MODE_OUTPUT;
  GPIO_InitStruct.Speed = LL_GPIO_SPEED_FREQ_LOW;
  GPIO_InitStruct.OutputType = LL_GPIO_OUTPUT_PUSHPULL;
  GPIO_InitStruct.Pull = LL_GPIO_PULL_NO;
  LL_GPIO_Init(GPIOC, &GPIO_InitStruct);

  /**/
  GPIO_InitStruct.Pin = LL_GPIO_PIN_9;
  GPIO_InitStruct.Mode = LL_GPIO_MODE_OUTPUT;
  GPIO_InitStruct.Speed = LL_GPIO_SPEED_FREQ_LOW;
  GPIO_InitStruct.OutputType = LL_GPIO_OUTPUT_PUSHPULL;
  GPIO_InitStruct.Pull = LL_GPIO_PULL_NO;
  LL_GPIO_Init(GPIOH, &GPIO_InitStruct);

  /**/
  GPIO_InitStruct.Pin = LL_GPIO_PIN_10;
  GPIO_InitStruct.Mode = LL_GPIO_MODE_OUTPUT;
  GPIO_InitStruct.Speed = LL_GPIO_SPEED_FREQ_LOW;
  GPIO_InitStruct.OutputType = LL_GPIO_OUTPUT_PUSHPULL;
  GPIO_InitStruct.Pull = LL_GPIO_PULL_NO;
  LL_GPIO_Init(GPIOH, &GPIO_InitStruct);

  /**/
  GPIO_InitStruct.Pin = LL_GPIO_PIN_1;
  GPIO_InitStruct.Mode = LL_GPIO_MODE_OUTPUT;
  GPIO_InitStruct.Speed = LL_GPIO_SPEED_FREQ_LOW;
  GPIO_InitStruct.OutputType = LL_GPIO_OUTPUT_PUSHPULL;
  GPIO_InitStruct.Pull = LL_GPIO_PULL_NO;
  LL_GPIO_Init(GPIOH, &GPIO_InitStruct);

  /**/
  GPIO_InitStruct.Pin = LL_GPIO_PIN_7;
  GPIO_InitStruct.Mode = LL_GPIO_MODE_OUTPUT;
  GPIO_InitStruct.Speed = LL_GPIO_SPEED_FREQ_LOW;
  GPIO_InitStruct.OutputType = LL_GPIO_OUTPUT_PUSHPULL;
  GPIO_InitStruct.Pull = LL_GPIO_PULL_NO;
  LL_GPIO_Init(GPIOE, &GPIO_InitStruct);

  /**/
  GPIO_InitStruct.Pin = LL_GPIO_PIN_8;
  GPIO_InitStruct.Mode = LL_GPIO_MODE_OUTPUT;
  GPIO_InitStruct.Speed = LL_GPIO_SPEED_FREQ_LOW;
  GPIO_InitStruct.OutputType = LL_GPIO_OUTPUT_PUSHPULL;
  GPIO_InitStruct.Pull = LL_GPIO_PULL_NO;
  LL_GPIO_Init(GPIOE, &GPIO_InitStruct);

  /**/
  GPIO_InitStruct.Pin = LL_GPIO_PIN_9;
  GPIO_InitStruct.Mode = LL_GPIO_MODE_OUTPUT;
  GPIO_InitStruct.Speed = LL_GPIO_SPEED_FREQ_LOW;
  GPIO_InitStruct.OutputType = LL_GPIO_OUTPUT_PUSHPULL;
  GPIO_InitStruct.Pull = LL_GPIO_PULL_NO;
  LL_GPIO_Init(GPIOE, &GPIO_InitStruct);

  /**/
  GPIO_InitStruct.Pin = LL_GPIO_PIN_12;
  GPIO_InitStruct.Mode = LL_GPIO_MODE_OUTPUT;
  GPIO_InitStruct.Speed = LL_GPIO_SPEED_FREQ_LOW;
  GPIO_InitStruct.OutputType = LL_GPIO_OUTPUT_PUSHPULL;
  GPIO_InitStruct.Pull = LL_GPIO_PULL_NO;
  LL_GPIO_Init(GPIOE, &GPIO_InitStruct);

  /**/
  GPIO_InitStruct.Pin = LL_GPIO_PIN_13;
  GPIO_InitStruct.Mode = LL_GPIO_MODE_OUTPUT;
  GPIO_InitStruct.Speed = LL_GPIO_SPEED_FREQ_LOW;
  GPIO_InitStruct.OutputType = LL_GPIO_OUTPUT_PUSHPULL;
  GPIO_InitStruct.Pull = LL_GPIO_PULL_NO;
  LL_GPIO_Init(GPIOE, &GPIO_InitStruct);

  /**/
  GPIO_InitStruct.Pin = LL_GPIO_PIN_14;
  GPIO_InitStruct.Mode = LL_GPIO_MODE_OUTPUT;
  GPIO_InitStruct.Speed = LL_GPIO_SPEED_FREQ_LOW;
  GPIO_InitStruct.OutputType = LL_GPIO_OUTPUT_PUSHPULL;
  GPIO_InitStruct.Pull = LL_GPIO_PULL_NO;
  LL_GPIO_Init(GPIOE, &GPIO_InitStruct);

  /**/
  GPIO_InitStruct.Pin = LL_GPIO_PIN_15;
  GPIO_InitStruct.Mode = LL_GPIO_MODE_OUTPUT;
  GPIO_InitStruct.Speed = LL_GPIO_SPEED_FREQ_LOW;
  GPIO_InitStruct.OutputType = LL_GPIO_OUTPUT_PUSHPULL;
  GPIO_InitStruct.Pull = LL_GPIO_PULL_NO;
  LL_GPIO_Init(GPIOE, &GPIO_InitStruct);

  /**/
  GPIO_InitStruct.Pin = LL_GPIO_PIN_12;
  GPIO_InitStruct.Mode = LL_GPIO_MODE_OUTPUT;
  GPIO_InitStruct.Speed = LL_GPIO_SPEED_FREQ_LOW;
  GPIO_InitStruct.OutputType = LL_GPIO_OUTPUT_PUSHPULL;
  GPIO_InitStruct.Pull = LL_GPIO_PULL_NO;
  LL_GPIO_Init(GPIOB, &GPIO_InitStruct);

  /**/
  GPIO_InitStruct.Pin = LL_GPIO_PIN_13;
  GPIO_InitStruct.Mode = LL_GPIO_MODE_OUTPUT;
  GPIO_InitStruct.Speed = LL_GPIO_SPEED_FREQ_LOW;
  GPIO_InitStruct.OutputType = LL_GPIO_OUTPUT_PUSHPULL;
  GPIO_InitStruct.Pull = LL_GPIO_PULL_NO;
  LL_GPIO_Init(GPIOB, &GPIO_InitStruct);

  /**/
  GPIO_InitStruct.Pin = LL_GPIO_PIN_14;
  GPIO_InitStruct.Mode = LL_GPIO_MODE_INPUT;
  GPIO_InitStruct.Pull = LL_GPIO_PULL_NO;
  LL_GPIO_Init(GPIOB, &GPIO_InitStruct);

  /**/
  GPIO_InitStruct.Pin = LL_GPIO_PIN_15;
  GPIO_InitStruct.Mode = LL_GPIO_MODE_INPUT;
  GPIO_InitStruct.Pull = LL_GPIO_PULL_NO;
  LL_GPIO_Init(GPIOB, &GPIO_InitStruct);

  /**/
  GPIO_InitStruct.Pin = LL_GPIO_PIN_8;
  GPIO_InitStruct.Mode = LL_GPIO_MODE_INPUT;
  GPIO_InitStruct.Pull = LL_GPIO_PULL_NO;
  LL_GPIO_Init(GPIOD, &GPIO_InitStruct);

  /**/
  GPIO_InitStruct.Pin = LL_GPIO_PIN_9;
  GPIO_InitStruct.Mode = LL_GPIO_MODE_INPUT;
  GPIO_InitStruct.Pull = LL_GPIO_PULL_NO;
  LL_GPIO_Init(GPIOD, &GPIO_InitStruct);

  /**/
  GPIO_InitStruct.Pin = LL_GPIO_PIN_10;
  GPIO_InitStruct.Mode = LL_GPIO_MODE_INPUT;
  GPIO_InitStruct.Pull = LL_GPIO_PULL_NO;
  LL_GPIO_Init(GPIOD, &GPIO_InitStruct);

  /**/
  GPIO_InitStruct.Pin = LL_GPIO_PIN_11;
  GPIO_InitStruct.Mode = LL_GPIO_MODE_INPUT;
  GPIO_InitStruct.Pull = LL_GPIO_PULL_NO;
  LL_GPIO_Init(GPIOD, &GPIO_InitStruct);

  /**/
  GPIO_InitStruct.Pin = LL_GPIO_PIN_12;
  GPIO_InitStruct.Mode = LL_GPIO_MODE_INPUT;
  GPIO_InitStruct.Pull = LL_GPIO_PULL_NO;
  LL_GPIO_Init(GPIOD, &GPIO_InitStruct);

  /**/
  GPIO_InitStruct.Pin = LL_GPIO_PIN_13;
  GPIO_InitStruct.Mode = LL_GPIO_MODE_INPUT;
  GPIO_InitStruct.Pull = LL_GPIO_PULL_NO;
  LL_GPIO_Init(GPIOD, &GPIO_InitStruct);

  /**/
  GPIO_InitStruct.Pin = LL_GPIO_PIN_14;
  GPIO_InitStruct.Mode = LL_GPIO_MODE_INPUT;
  GPIO_InitStruct.Pull = LL_GPIO_PULL_NO;
  LL_GPIO_Init(GPIOD, &GPIO_InitStruct);

  /**/
  GPIO_InitStruct.Pin = LL_GPIO_PIN_15;
  GPIO_InitStruct.Mode = LL_GPIO_MODE_INPUT;
  GPIO_InitStruct.Pull = LL_GPIO_PULL_NO;
  LL_GPIO_Init(GPIOD, &GPIO_InitStruct);

  /**/
  GPIO_InitStruct.Pin = LL_GPIO_PIN_6;
  GPIO_InitStruct.Mode = LL_GPIO_MODE_INPUT;
  GPIO_InitStruct.Pull = LL_GPIO_PULL_NO;
  LL_GPIO_Init(GPIOC, &GPIO_InitStruct);

  /**/
  GPIO_InitStruct.Pin = LL_GPIO_PIN_7;
  GPIO_InitStruct.Mode = LL_GPIO_MODE_INPUT;
  GPIO_InitStruct.Pull = LL_GPIO_PULL_NO;
  LL_GPIO_Init(GPIOC, &GPIO_InitStruct);

  /**/
  GPIO_InitStruct.Pin = LL_GPIO_PIN_8;
  GPIO_InitStruct.Mode = LL_GPIO_MODE_INPUT;
  GPIO_InitStruct.Pull = LL_GPIO_PULL_NO;
  LL_GPIO_Init(GPIOC, &GPIO_InitStruct);

  /**/
  GPIO_InitStruct.Pin = LL_GPIO_PIN_8;
  GPIO_InitStruct.Mode = LL_GPIO_MODE_OUTPUT;
  GPIO_InitStruct.Speed = LL_GPIO_SPEED_FREQ_LOW;
  GPIO_InitStruct.OutputType = LL_GPIO_OUTPUT_PUSHPULL;
  GPIO_InitStruct.Pull = LL_GPIO_PULL_NO;
  LL_GPIO_Init(GPIOA, &GPIO_InitStruct);

  /**/
  GPIO_InitStruct.Pin = LL_GPIO_PIN_15;
  GPIO_InitStruct.Mode = LL_GPIO_MODE_OUTPUT;
  GPIO_InitStruct.Speed = LL_GPIO_SPEED_FREQ_LOW;
  GPIO_InitStruct.OutputType = LL_GPIO_OUTPUT_PUSHPULL;
  GPIO_InitStruct.Pull = LL_GPIO_PULL_NO;
  LL_GPIO_Init(GPIOA, &GPIO_InitStruct);

  /**/
  GPIO_InitStruct.Pin = LL_GPIO_PIN_0;
  GPIO_InitStruct.Mode = LL_GPIO_MODE_OUTPUT;
  GPIO_InitStruct.Speed = LL_GPIO_SPEED_FREQ_LOW;
  GPIO_InitStruct.OutputType = LL_GPIO_OUTPUT_PUSHPULL;
  GPIO_InitStruct.Pull = LL_GPIO_PULL_NO;
  LL_GPIO_Init(GPIOD, &GPIO_InitStruct);

  /**/
  LL_SYSCFG_SetEXTISource(LL_SYSCFG_EXTI_PORTC, LL_SYSCFG_EXTI_LINE1);

  /**/
  LL_SYSCFG_SetEXTISource(LL_SYSCFG_EXTI_PORTC, LL_SYSCFG_EXTI_LINE10);

  /**/
  LL_GPIO_SetPinPull(GPIOC, LL_GPIO_PIN_1, LL_GPIO_PULL_NO);

  /**/
  LL_GPIO_SetPinPull(GPIOC, LL_GPIO_PIN_10, LL_GPIO_PULL_NO);

  /**/
  LL_GPIO_SetPinMode(GPIOC, LL_GPIO_PIN_1, LL_GPIO_MODE_INPUT);

  /**/
  LL_GPIO_SetPinMode(GPIOC, LL_GPIO_PIN_10, LL_GPIO_MODE_INPUT);

  /**/
  EXTI_InitStruct.Line_0_31 = LL_EXTI_LINE_1;
  EXTI_InitStruct.LineCommand = ENABLE;
  EXTI_InitStruct.Mode = LL_EXTI_MODE_IT;
  EXTI_InitStruct.Trigger = LL_EXTI_TRIGGER_RISING;
  LL_EXTI_Init(&EXTI_InitStruct);

  /**/
  EXTI_InitStruct.Line_0_31 = LL_EXTI_LINE_10;
  EXTI_InitStruct.LineCommand = ENABLE;
  EXTI_InitStruct.Mode = LL_EXTI_MODE_IT;
  EXTI_InitStruct.Trigger = LL_EXTI_TRIGGER_RISING;
  LL_EXTI_Init(&EXTI_InitStruct);

}

void _Error_Handler(char * file, int line)
{
  while(1)
  {
  }
}

/************************ (C) COPYRIGHT STMicroelectronics *****END OF FILE****/
